# AT32F425xx_v2 register map
Vendor: Keil; Series: AT32F425; File version: 1.0
CPU: CM4 r0p1, little endian, no MPU, FPU, 4 interrupt priority bits
Registers are 32-bit, read-write, reset 0x0 unless marked. A register's access mark holds for its fields unless they carry their own. Offsets are from the block's base; [hi:lo] are bit positions.

## WWDT — Window watchdog
Base 0x40002C00
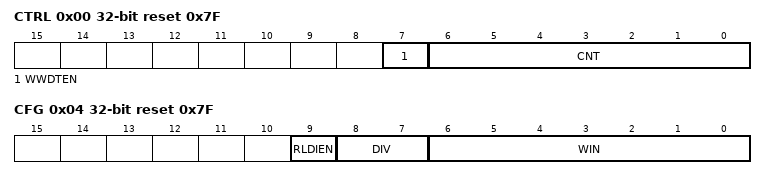
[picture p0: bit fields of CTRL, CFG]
0x00 CTRL reset 0x7F — Control register
  [7] WWDTEN — Window watchdog enable
  [6:0] CNT — Decrement counter
0x04 CFG reset 0x7F — Configuration register
  [9] RLDIEN — Reload counter interrupt
  [8:7] DIV — Clock division value
  [6:0] WIN — Window value
0x08 STS — Status register
  [0] RLDF — Reload counter interrupt flag

## TMR6 — Basic timer
Base 0x40001000
Same registers: TMR7 0x40001400
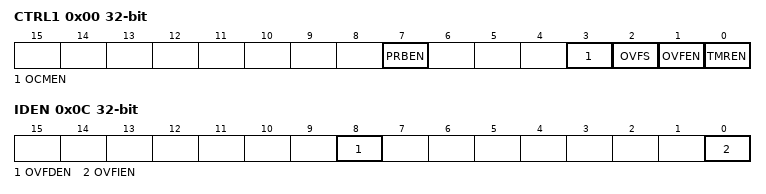
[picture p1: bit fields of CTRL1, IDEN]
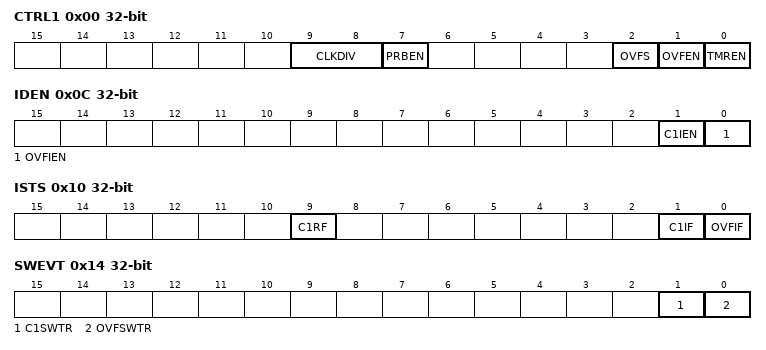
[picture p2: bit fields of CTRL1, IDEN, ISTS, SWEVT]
0x00 CTRL1 — Control register 1
  [7] PRBEN — Period buffer enable
  [3] OCMEN — One cycle mode enable
  [2] OVFS — Overflow event source
  [1] OVFEN — Overflow event enable
  [0] TMREN — TMR enable
0x04 CTRL2 — Control register 2
  [6:4] PTOS — Primary TMR output selection
0x0C IDEN — Interrupt/DMA enable register
  [8] OVFDEN — Overflow DMA request enable
  [0] OVFIEN — Overflow interrupt enable
0x10 ISTS — Interrupt status register
  [0] OVFIF — Overflow interrupt flag
0x14 SWEVT — Software event register
  [0] OVFSWTR — Overflow event triggered by software
0x24 CVAL — Counter value
  [15:0] CVAL
0x28 DIV — Divider value
  [15:0] DIV
0x2C PR — Period value
  [15:0] PR

## TMR13 — General-purpose-timers
Base 0x40001C00
0x00 CTRL1 — Control register 1
  [9:8] CLKDIV — Clock divider
  [7] PRBEN — Period buffer enable
  [2] OVFS — Overflow event source
  [1] OVFEN — Overflow event enable
  [0] TMREN — TMR enable
0x0C IDEN — Interrupt/DMA enable register
  [1] C1IEN — Channel 1 interrupt enable
  [0] OVFIEN — Overflow interrupt enable
0x10 ISTS — Interrupt status register
  [9] C1RF — Channel 1 recapture flag
  [1] C1IF — Channel 1 interrupt flag
  [0] OVFIF — Overflow interrupt flag
0x14 SWEVT — Software event register
  [1] C1SWTR — Channel 1 event triggered by software
  [0] OVFSWTR — Overflow event triggered by software
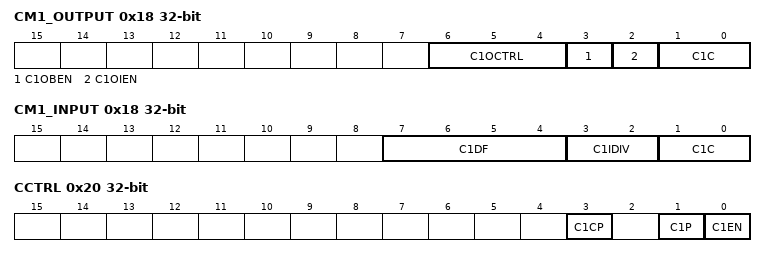
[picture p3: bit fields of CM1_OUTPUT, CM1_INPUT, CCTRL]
0x18 CM1_OUTPUT — Channel output mode register
  [6:4] C1OCTRL — Channel 1 output control
  [3] C1OBEN — Channel 1 output buffer enable
  [2] C1OIEN — Channel 1 output immediately enable
  [1:0] C1C — Channel 1 configure
0x18 CM1_INPUT (alternate view of CM1_OUTPUT) — Channel input mode register 1
  [7:4] C1DF — Channel 1 digital filter
  [3:2] C1IDIV — Channel 1 input divider
  [1:0] C1C — Channel 1 configure
0x20 CCTRL — Channel control register
  [3] C1CP — Channel 1 complementary polarity
  [1] C1P — Channel 1 Polarity
  [0] C1EN — Channel 1 enable
0x24 CVAL — Counter value
  [15:0] CVAL
0x28 DIV — Divider value
  [15:0] DIV
0x2C PR — Period value
  [15:0] PR
0x34 C1DT — Channel 1 data register
  [15:0] C1DT

## TMR14 — General-purpose-timers
Base 0x40002000
Registers as TMR13; these are added or differ:
0x50 RMP — TMR14 channel 1 input remap
  [7:6] TMR14_CH1_IRMP

## TMR16 — General-purpose-timers
Base 0x40014400
Same registers: TMR17 0x40014800
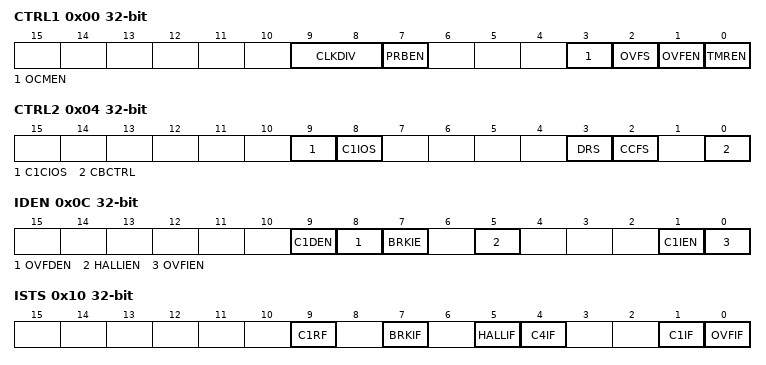
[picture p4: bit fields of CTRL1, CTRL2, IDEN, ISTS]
0x00 CTRL1 — Control register 1
  [9:8] CLKDIV — Clock divider
  [7] PRBEN — Period buffer enable
  [3] OCMEN — One cycle mode enable
  [2] OVFS — Overflow event source
  [1] OVFEN — Overflow event enable
  [0] TMREN — TMR enable
0x04 CTRL2 — Control register 2
  [9] C1CIOS — Channel 1 complementary idle output state
  [8] C1IOS — Channel 1 idle output state
  [3] DRS — DMA request source
  [2] CCFS — Channel control bit flash select
  [0] CBCTRL — Channel buffer control
0x0C IDEN — Interrupt/DMA enable register
  [9] C1DEN — Channel 1 DMA request enable
  [8] OVFDEN — Overflow DMA request enable
  [7] BRKIE — Brake interrupt enable
  [5] HALLIEN — HALL interrupt enable
  [1] C1IEN — Channel 1 interrupt enable
  [0] OVFIEN — Overflow interrupt enable
0x10 ISTS — Interrupt status register
  [9] C1RF — Channel 1 recapture flag
  [7] BRKIF — Brake interrupt flag
  [5] HALLIF — HALL interrupt flag
  [4] C4IF — Channel 4 interrupt flag
  [1] C1IF — Channel 1 interrupt flag
  [0] OVFIF — Overflow interrupt flag
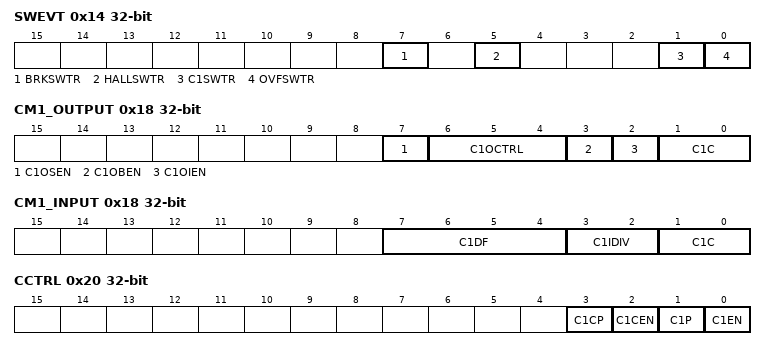
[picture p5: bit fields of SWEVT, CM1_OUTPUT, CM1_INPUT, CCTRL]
0x14 SWEVT — Software event register
  [7] BRKSWTR — Brake event triggered by software
  [5] HALLSWTR — HALL event triggered by software
  [1] C1SWTR — Channel 1 event triggered by software
  [0] OVFSWTR — Overflow event triggered by software
0x18 CM1_OUTPUT — Channel output mode register
  [7] C1OSEN — Channel 1 output switch enable
  [6:4] C1OCTRL — Channel 1 output control
  [3] C1OBEN — Channel 1 output buffer enable
  [2] C1OIEN — Channel 1 output immediately enable
  [1:0] C1C — Channel 1 configure
0x18 CM1_INPUT (alternate view of CM1_OUTPUT) — Channel input mode register 1
  [7:4] C1DF — Channel 1 digital filter
  [3:2] C1IDIV — Channel 1 input divider
  [1:0] C1C — Channel 1 configure
0x20 CCTRL — Channel control register
  [3] C1CP — Channel 1 complementary polarity
  [2] C1CEN — Channel 1 complementary enable
  [1] C1P — Channel 1 Polarity
  [0] C1EN — Channel 1 enable
0x24 CVAL — Counter value
  [15:0] CVAL
0x28 DIV — Divider value
  [15:0] DIV
0x2C PR — Period value
  [15:0] PR
0x30 RPR — Repetition of period value
  [7:0] RPR
0x34 C1DT — Channel 1 data register
  [15:0] C1DT
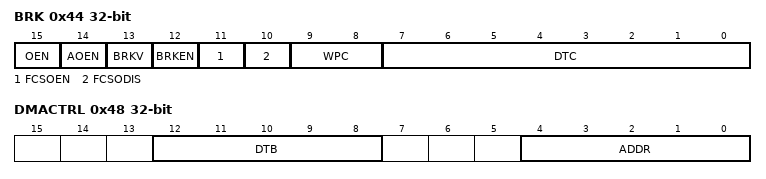
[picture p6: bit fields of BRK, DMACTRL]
0x44 BRK — Brake register
  [15] OEN — Output enable
  [14] AOEN — Automatic output enable
  [13] BRKV — Brake input validity
  [12] BRKEN — Brake enable
  [11] FCSOEN — Frozen channel status when holistic output enable
  [10] FCSODIS — Frozen channel status when holistic output disable
  [9:8] WPC — Write protected configuration
  [7:0] DTC — Dead-time configuration
0x48 DMACTRL — DMA control register
  [12:8] DTB — DMA transfer bytes
  [4:0] ADDR — DMA transfer address offset
0x4C DMADT — DMA data register
  [15:0] DMADT
